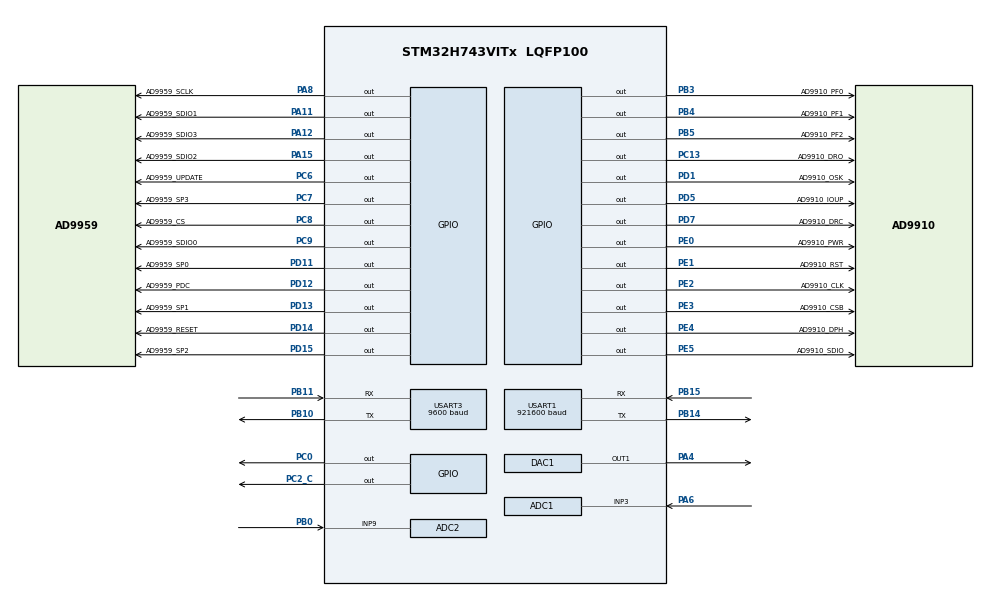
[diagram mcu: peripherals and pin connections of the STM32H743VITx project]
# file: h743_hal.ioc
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ADC1.Channel-0\#ChannelRegularConversion=ADC_CHANNEL_3
ADC1.ConversionDataManagement=ADC_CONVERSIONDATA_DMA_CIRCULAR
ADC1.ExternalTrigConv=ADC_EXTERNALTRIG_T6_TRGO
ADC1.NbrOfConversionFlag=1
ADC1.OffsetNumber-0\#ChannelRegularConversion=ADC_OFFSET_NONE
ADC1.OffsetSignedSaturation-0\#ChannelRegularConversion=DISABLE
ADC1.Rank-0\#ChannelRegularConversion=1
ADC1.Resolution=ADC_RESOLUTION_12B
ADC1.SamplingTime-0\#ChannelRegularConversion=ADC_SAMPLETIME_1CYCLE_5
ADC1.master=1
ADC2.Channel-7\#ChannelRegularConversion=ADC_CHANNEL_9
ADC2.ConversionDataManagement=ADC_CONVERSIONDATA_DMA_CIRCULAR
ADC2.ExternalTrigConv=ADC_EXTERNALTRIG_T6_TRGO
ADC2.NbrOfConversionFlag=1
ADC2.OffsetNumber-7\#ChannelRegularConversion=ADC_OFFSET_NONE
ADC2.OffsetSignedSaturation-7\#ChannelRegularConversion=DISABLE
ADC2.Rank-7\#ChannelRegularConversion=1
ADC2.Resolution=ADC_RESOLUTION_12B
ADC2.SamplingTime-7\#ChannelRegularConversion=ADC_SAMPLETIME_16CYCLES_5
CORTEX_M7.AccessPermission_Spec=MPU_REGION_FULL_ACCESS
CORTEX_M7.BaseAddress_Spec=0x24000000
CORTEX_M7.CPU_DCache=Enabled
CORTEX_M7.CPU_ICache=Enabled
CORTEX_M7.DisableExec_Spec=MPU_INSTRUCTION_ACCESS_ENABLE
CORTEX_M7.IsShareable_Spec=MPU_ACCESS_NOT_SHAREABLE
CORTEX_M7.Size_Spec=MPU_REGION_SIZE_128KB
CORTEX_M7.SubRegionDisable_Spec=0x00
CORTEX_M7.TypeExtField_Spec=MPU_TEX_LEVEL1
CORTEX_M7.default_mode_Activation=1
DAC1.DAC1_OutputBuffer-DAC_OUT1=DAC_OUTPUTBUFFER_ENABLE
DAC1.DAC_Channel-DAC_OUT1=DAC_CHANNEL_1
DAC1.DAC_Trigger-DAC_OUT1=DAC_TRIGGER_T6_TRGO
Dma.ADC1.0.Direction=DMA_PERIPH_TO_MEMORY
Dma.ADC1.0.EventEnable=DISABLE
Dma.ADC1.0.FIFOMode=DMA_FIFOMODE_DISABLE
Dma.ADC1.0.Instance=DMA1_Stream0
Dma.ADC1.0.MemDataAlignment=DMA_MDATAALIGN_HALFWORD
Dma.ADC1.0.MemInc=DMA_MINC_ENABLE
Dma.ADC1.0.Mode=DMA_CIRCULAR
Dma.ADC1.0.PeriphDataAlignment=DMA_PDATAALIGN_HALFWORD
Dma.ADC1.0.PeriphInc=DMA_PINC_DISABLE
Dma.ADC1.0.Polarity=HAL_DMAMUX_REQ_GEN_RISING
Dma.ADC1.0.Priority=DMA_PRIORITY_LOW
Dma.ADC1.0.RequestNumber=1
Dma.ADC1.0.SignalID=NONE
Dma.ADC1.0.SyncEnable=DISABLE
Dma.ADC1.0.SyncPolarity=HAL_DMAMUX_SYNC_NO_EVENT
Dma.ADC1.0.SyncRequestNumber=1
Dma.ADC1.0.SyncSignalID=NONE
Dma.ADC2.4.Direction=DMA_PERIPH_TO_MEMORY
Dma.ADC2.4.EventEnable=DISABLE
Dma.ADC2.4.FIFOMode=DMA_FIFOMODE_DISABLE
Dma.ADC2.4.Instance=DMA1_Stream4
Dma.ADC2.4.MemDataAlignment=DMA_MDATAALIGN_HALFWORD
Dma.ADC2.4.MemInc=DMA_MINC_ENABLE
Dma.ADC2.4.Mode=DMA_CIRCULAR
Dma.ADC2.4.PeriphDataAlignment=DMA_PDATAALIGN_HALFWORD
Dma.ADC2.4.PeriphInc=DMA_PINC_DISABLE
Dma.ADC2.4.Polarity=HAL_DMAMUX_REQ_GEN_RISING
Dma.ADC2.4.Priority=DMA_PRIORITY_VERY_HIGH
Dma.ADC2.4.RequestNumber=1
Dma.ADC2.4.SignalID=NONE
Dma.ADC2.4.SyncEnable=DISABLE
Dma.ADC2.4.SyncPolarity=HAL_DMAMUX_SYNC_NO_EVENT
Dma.ADC2.4.SyncRequestNumber=1
Dma.ADC2.4.SyncSignalID=NONE
Dma.DAC1_CH1.3.Direction=DMA_MEMORY_TO_PERIPH
Dma.DAC1_CH1.3.EventEnable=DISABLE
Dma.DAC1_CH1.3.FIFOMode=DMA_FIFOMODE_DISABLE
Dma.DAC1_CH1.3.Instance=DMA1_Stream3
Dma.DAC1_CH1.3.MemDataAlignment=DMA_MDATAALIGN_HALFWORD
Dma.DAC1_CH1.3.MemInc=DMA_MINC_ENABLE
Dma.DAC1_CH1.3.Mode=DMA_CIRCULAR
Dma.DAC1_CH1.3.PeriphDataAlignment=DMA_PDATAALIGN_HALFWORD
Dma.DAC1_CH1.3.PeriphInc=DMA_PINC_DISABLE
Dma.DAC1_CH1.3.Polarity=HAL_DMAMUX_REQ_GEN_RISING
Dma.DAC1_CH1.3.Priority=DMA_PRIORITY_VERY_HIGH
Dma.DAC1_CH1.3.RequestNumber=1
Dma.DAC1_CH1.3.SignalID=NONE
Dma.DAC1_CH1.3.SyncEnable=DISABLE
Dma.DAC1_CH1.3.SyncPolarity=HAL_DMAMUX_SYNC_NO_EVENT
Dma.DAC1_CH1.3.SyncRequestNumber=1
Dma.DAC1_CH1.3.SyncSignalID=NONE
Dma.Request0=ADC1
Dma.Request1=USART1_RX
Dma.Request2=USART3_RX
Dma.Request3=DAC1_CH1
Dma.Request4=ADC2
Dma.USART1_RX.1.Direction=DMA_PERIPH_TO_MEMORY
Dma.USART1_RX.1.EventEnable=DISABLE
Dma.USART1_RX.1.FIFOMode=DMA_FIFOMODE_DISABLE
Dma.USART1_RX.1.Instance=DMA1_Stream1
Dma.USART1_RX.1.MemDataAlignment=DMA_MDATAALIGN_BYTE
Dma.USART1_RX.1.MemInc=DMA_MINC_ENABLE
Dma.USART1_RX.1.Mode=DMA_NORMAL
Dma.USART1_RX.1.PeriphDataAlignment=DMA_PDATAALIGN_BYTE
Dma.USART1_RX.1.PeriphInc=DMA_PINC_DISABLE
Dma.USART1_RX.1.Polarity=HAL_DMAMUX_REQ_GEN_RISING
Dma.USART1_RX.1.Priority=DMA_PRIORITY_LOW
Dma.USART1_RX.1.RequestNumber=1
Dma.USART1_RX.1.SignalID=NONE
Dma.USART1_RX.1.SyncEnable=DISABLE
Dma.USART1_RX.1.SyncPolarity=HAL_DMAMUX_SYNC_NO_EVENT
Dma.USART1_RX.1.SyncRequestNumber=1
Dma.USART1_RX.1.SyncSignalID=NONE
Dma.USART3_RX.2.Direction=DMA_PERIPH_TO_MEMORY
Dma.USART3_RX.2.EventEnable=DISABLE
Dma.USART3_RX.2.FIFOMode=DMA_FIFOMODE_DISABLE
Dma.USART3_RX.2.Instance=DMA1_Stream2
Dma.USART3_RX.2.MemDataAlignment=DMA_MDATAALIGN_BYTE
Dma.USART3_RX.2.MemInc=DMA_MINC_ENABLE
Dma.USART3_RX.2.Mode=DMA_NORMAL
Dma.USART3_RX.2.PeriphDataAlignment=DMA_PDATAALIGN_BYTE
Dma.USART3_RX.2.PeriphInc=DMA_PINC_DISABLE
Dma.USART3_RX.2.Polarity=HAL_DMAMUX_REQ_GEN_RISING
Dma.USART3_RX.2.Priority=DMA_PRIORITY_LOW
Dma.USART3_RX.2.RequestNumber=1
Dma.USART3_RX.2.SignalID=NONE
Dma.USART3_RX.2.SyncEnable=DISABLE
Dma.USART3_RX.2.SyncPolarity=HAL_DMAMUX_SYNC_NO_EVENT
Dma.USART3_RX.2.SyncRequestNumber=1
Dma.USART3_RX.2.SyncSignalID=NONE
Mcu.Family=STM32H7
Mcu.Name=STM32H743VITx
Mcu.Package=LQFP100
NVIC.DMA1_Stream0_IRQn=true\:0\:0\:false\:false\:true\:false\:true\:true
NVIC.DMA1_Stream1_IRQn=true\:0\:0\:false\:false\:true\:false\:true\:true
NVIC.DMA1_Stream2_IRQn=true\:0\:0\:false\:false\:true\:false\:true\:true
NVIC.DMA1_Stream3_IRQn=true\:0\:0\:false\:false\:true\:false\:true\:true
NVIC.DMA1_Stream4_IRQn=true\:0\:0\:false\:false\:true\:false\:true\:true
NVIC.PriorityGroup=NVIC_PRIORITYGROUP_4
NVIC.USART3_IRQn=true\:0\:0\:false\:false\:true\:true\:true\:true
PA11.GPIO_Label=AD9959_SDIO1
PA11.Signal=GPIO_Output
PA12.GPIO_Label=AD9959_SDIO3
PA12.Signal=GPIO_Output
PA13\ (JTMS/SWDIO).Mode=Serial_Wire
PA13\ (JTMS/SWDIO).Signal=DEBUG_JTMS-SWDIO
PA14\ (JTCK/SWCLK).Mode=Serial_Wire
PA14\ (JTCK/SWCLK).Signal=DEBUG_JTCK-SWCLK
PA15\ (JTDI).GPIO_Label=AD9959_SDIO2
PA15\ (JTDI).Signal=GPIO_Output
PA4.Signal=COMP_DAC11_group
PA6.Signal=ADCx_INP3
PA8.GPIO_Label=AD9959_SCLK
PA8.Signal=GPIO_Output
PB0.Signal=ADCx_INP9
PB10.Mode=Asynchronous
PB10.Signal=USART3_TX
PB11.Mode=Asynchronous
PB11.Signal=USART3_RX
PB14.Mode=Asynchronous
PB14.Signal=USART1_TX
PB15.Mode=Asynchronous
PB15.Signal=USART1_RX
PB3\ (JTDO/TRACESWO).GPIO_Label=AD9910_PF0
PB3\ (JTDO/TRACESWO).Signal=GPIO_Output
PB4\ (NJTRST).GPIO_Label=AD9910_PF1
PB4\ (NJTRST).Signal=GPIO_Output
PB5.GPIO_Label=AD9910_PF2
PB5.Signal=GPIO_Output
PC0.Signal=GPIO_Output
PC13.GPIO_Label=AD9910_DRO
PC13.Signal=GPIO_Output
PC14-OSC32_IN\ (OSC32_IN).Mode=LSE-External-Oscillator
PC14-OSC32_IN\ (OSC32_IN).Signal=RCC_OSC32_IN
PC15-OSC32_OUT\ (OSC32_OUT).Mode=LSE-External-Oscillator
PC15-OSC32_OUT\ (OSC32_OUT).Signal=RCC_OSC32_OUT
PC2_C.Signal=GPIO_Output
PC6.GPIO_Label=AD9959_UPDATE
PC6.Signal=GPIO_Output
PC7.GPIO_Label=AD9959_SP3
PC7.Signal=GPIO_Output
PC8.GPIO_Label=AD9959_CS
PC8.Signal=GPIO_Output
PC9.GPIO_Label=AD9959_SDIO0
PC9.Signal=GPIO_Output
PD1.GPIO_Label=AD9910_OSK
PD1.Signal=GPIO_Output
PD11.GPIO_Label=AD9959_SP0
PD11.Signal=GPIO_Output
PD12.GPIO_Label=AD9959_PDC
PD12.Signal=GPIO_Output
PD13.GPIO_Label=AD9959_SP1
PD13.Signal=GPIO_Output
PD14.GPIO_Label=AD9959_RESET
PD14.Signal=GPIO_Output
PD15.GPIO_Label=AD9959_SP2
PD15.Signal=GPIO_Output
PD5.GPIO_Label=AD9910_IOUP
PD5.Signal=GPIO_Output
PD7.GPIO_Label=AD9910_DRC
PD7.Signal=GPIO_Output
PE0.GPIO_Label=AD9910_PWR
PE0.Signal=GPIO_Output
PE1.GPIO_Label=AD9910_RST
PE1.Signal=GPIO_Output
PE2.GPIO_Label=AD9910_CLK
PE2.GPIO_Speed=GPIO_SPEED_FREQ_VERY_HIGH
PE2.Signal=GPIO_Output
PE3.GPIO_Label=AD9910_CSB
PE3.Signal=GPIO_Output
PE4.GPIO_Label=AD9910_DPH
PE4.Signal=GPIO_Output
PE5.GPIO_Label=AD9910_SDIO
PE5.Signal=GPIO_Output
PH0-OSC_IN\ (PH0).Mode=HSE-External-Oscillator
PH0-OSC_IN\ (PH0).Signal=RCC_OSC_IN
PH1-OSC_OUT\ (PH1).Mode=HSE-External-Oscillator
PH1-OSC_OUT\ (PH1).Signal=RCC_OSC_OUT
ProjectManager.HeapSize=0x200
ProjectManager.StackSize=0x400
ProjectManager.TargetToolchain=MDK-ARM V5.32
RCC.ADCFreq_Value=75000000
RCC.APB1Freq_Value=120000000
RCC.APB2Freq_Value=120000000
RCC.APB3Freq_Value=120000000
RCC.APB4Freq_Value=120000000
RCC.CortexFreq_Value=480000000
RCC.D1PPRE=RCC_APB3_DIV2
RCC.D2PPRE1=RCC_APB1_DIV2
RCC.D2PPRE2=RCC_APB2_DIV2
RCC.D3PPRE=RCC_APB4_DIV2
RCC.DIVM1=5
RCC.DIVM2=2
RCC.DIVN1=192
RCC.DIVN2=12
RCC.HCLKFreq_Value=240000000
RCC.HPRE=RCC_HCLK_DIV2
RCC.PLL2FRACN=0
RCC.PLL3FRACN=0
RCC.PLLFRACN=0
RCC.PLLSourceVirtual=RCC_PLLSOURCE_HSE
RCC.SYSCLKFreq_VALUE=480000000
RCC.SYSCLKSource=RCC_SYSCLKSOURCE_PLLCLK
RCC.USBFreq_Value=480000000
SH.ADCx_INP3.0=ADC2_INP3
SH.ADCx_INP3.1=ADC1_INP3,IN3-Single-Ended
SH.ADCx_INP9.0=ADC2_INP9,IN9-Single-Ended
SH.COMP_DAC11_group.0=DAC1_OUT1,DAC_OUT1
TIM6.AutoReloadPreload=TIM_AUTORELOAD_PRELOAD_ENABLE
TIM6.Period=40-1
TIM6.Prescaler=4-1
TIM6.TIM_MasterOutputTrigger=TIM_TRGO_UPDATE
USART1.BaudRate=921600
USART1.VirtualMode-Asynchronous=VM_ASYNC
USART3.BaudRate=9600
USART3.VirtualMode-Asynchronous=VM_ASYNC
VP_MEMORYMAP_VS_MEMORYMAP.Mode=CurAppReg
VP_TIM6_VS_ClockSourceINT.Mode=Enable_Timer
board=custom

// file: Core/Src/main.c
/* USER CODE BEGIN Header */
/**
  ******************************************************************************
  * @file           : main.c
  * @brief          : Main program body
  ******************************************************************************
  * @attention
  *
  * Copyright (c) 2026 STMicroelectronics.
  * All rights reserved.
  *
  * This software is licensed under terms that can be found in the LICENSE file
  * in the root directory of this software component.
  * If no LICENSE file comes with this software, it is provided AS-IS.
  *
  ******************************************************************************
  */
/* USER CODE END Header */
#include "main.h"
#include "adc.h"
#include "dac.h"
#include "dma.h"
#include "tim.h"
#include "usart.h"
#include "gpio.h"

/* USER CODE BEGIN Includes */
#include "rlc_app.h"

/* USER CODE END Includes */

void SystemClock_Config(void);
void PeriphCommonClock_Config(void);
static void MPU_Config(void);

int main(void)
{

  /* MPU Configuration--------------------------------------------------------*/
  MPU_Config();

  /* Enable the CPU Cache */

  /* Enable I-Cache---------------------------------------------------------*/
  SCB_EnableICache();

  /* Enable D-Cache---------------------------------------------------------*/
  SCB_EnableDCache();

  /* MCU Configuration--------------------------------------------------------*/

  /* Reset of all peripherals, Initializes the Flash interface and the Systick. */
  HAL_Init();

  /* Configure the system clock */
  SystemClock_Config();

  /* Configure the peripherals common clocks */
  PeriphCommonClock_Config();

  /* Initialize all configured peripherals */
  MX_GPIO_Init();
  MX_DMA_Init();
  MX_ADC1_Init();
  MX_USART3_UART_Init();
  MX_USART1_UART_Init();
  MX_DAC1_Init();
  MX_TIM6_Init();
  MX_ADC2_Init();
  /* USER CODE BEGIN 2 */
  rlc_app_init();
  /* USER CODE END 2 */

  /* Infinite loop */
  while (1)
  {

    /* USER CODE BEGIN 3 */
    rlc_app_task();
  }
  /* USER CODE END 3 */
}

void SystemClock_Config(void)
{
  RCC_OscInitTypeDef RCC_OscInitStruct = {0};
  RCC_ClkInitTypeDef RCC_ClkInitStruct = {0};

  /** Supply configuration update enable
  */
  HAL_PWREx_ConfigSupply(PWR_LDO_SUPPLY);

  /** Configure the main internal regulator output voltage
  */
  __HAL_PWR_VOLTAGESCALING_CONFIG(PWR_REGULATOR_VOLTAGE_SCALE0);

  while(!__HAL_PWR_GET_FLAG(PWR_FLAG_VOSRDY)) {}

  /** Initializes the RCC Oscillators according to the specified parameters
  * in the RCC_OscInitTypeDef structure.
  */
  RCC_OscInitStruct.OscillatorType = RCC_OSCILLATORTYPE_HSE;
  RCC_OscInitStruct.HSEState = RCC_HSE_ON;
  RCC_OscInitStruct.PLL.PLLState = RCC_PLL_ON;
  RCC_OscInitStruct.PLL.PLLSource = RCC_PLLSOURCE_HSE;
  RCC_OscInitStruct.PLL.PLLM = 5;
  RCC_OscInitStruct.PLL.PLLN = 192;
  RCC_OscInitStruct.PLL.PLLP = 2;
  RCC_OscInitStruct.PLL.PLLQ = 2;
  RCC_OscInitStruct.PLL.PLLR = 2;
  RCC_OscInitStruct.PLL.PLLRGE = RCC_PLL1VCIRANGE_2;
  RCC_OscInitStruct.PLL.PLLVCOSEL = RCC_PLL1VCOWIDE;
  RCC_OscInitStruct.PLL.PLLFRACN = 0;
  if (HAL_RCC_OscConfig(&RCC_OscInitStruct) != HAL_OK)
  {
    Error_Handler();
  }

  /** Initializes the CPU, AHB and APB buses clocks
  */
  RCC_ClkInitStruct.ClockType = RCC_CLOCKTYPE_HCLK|RCC_CLOCKTYPE_SYSCLK
                              |RCC_CLOCKTYPE_PCLK1|RCC_CLOCKTYPE_PCLK2
                              |RCC_CLOCKTYPE_D3PCLK1|RCC_CLOCKTYPE_D1PCLK1;
  RCC_ClkInitStruct.SYSCLKSource = RCC_SYSCLKSOURCE_PLLCLK;
  RCC_ClkInitStruct.SYSCLKDivider = RCC_SYSCLK_DIV1;
  RCC_ClkInitStruct.AHBCLKDivider = RCC_HCLK_DIV2;
  RCC_ClkInitStruct.APB3CLKDivider = RCC_APB3_DIV2;
  RCC_ClkInitStruct.APB1CLKDivider = RCC_APB1_DIV2;
  RCC_ClkInitStruct.APB2CLKDivider = RCC_APB2_DIV2;
  RCC_ClkInitStruct.APB4CLKDivider = RCC_APB4_DIV2;

  if (HAL_RCC_ClockConfig(&RCC_ClkInitStruct, FLASH_LATENCY_4) != HAL_OK)
  {
    Error_Handler();
  }
}

void PeriphCommonClock_Config(void)
{
  RCC_PeriphCLKInitTypeDef PeriphClkInitStruct = {0};

  /** Initializes the peripherals clock
  */
  PeriphClkInitStruct.PeriphClockSelection = RCC_PERIPHCLK_ADC;
  PeriphClkInitStruct.PLL2.PLL2M = 2;
  PeriphClkInitStruct.PLL2.PLL2N = 12;
  PeriphClkInitStruct.PLL2.PLL2P = 2;
  PeriphClkInitStruct.PLL2.PLL2Q = 2;
  PeriphClkInitStruct.PLL2.PLL2R = 2;
  PeriphClkInitStruct.PLL2.PLL2RGE = RCC_PLL2VCIRANGE_3;
  PeriphClkInitStruct.PLL2.PLL2VCOSEL = RCC_PLL2VCOMEDIUM;
  PeriphClkInitStruct.PLL2.PLL2FRACN = 0;
  PeriphClkInitStruct.AdcClockSelection = RCC_ADCCLKSOURCE_PLL2;
  if (HAL_RCCEx_PeriphCLKConfig(&PeriphClkInitStruct) != HAL_OK)
  {
    Error_Handler();
  }
}

 /* MPU Configuration */

void MPU_Config(void)
{
  MPU_Region_InitTypeDef MPU_InitStruct = {0};

  /* Disables the MPU */
  HAL_MPU_Disable();

  /** Initializes and configures the Region and the memory to be protected
  */
  MPU_InitStruct.Enable = MPU_REGION_ENABLE;
  MPU_InitStruct.Number = MPU_REGION_NUMBER0;
  MPU_InitStruct.BaseAddress = 0x24000000;
  MPU_InitStruct.Size = MPU_REGION_SIZE_128KB;
  MPU_InitStruct.SubRegionDisable = 0x00;
  MPU_InitStruct.TypeExtField = MPU_TEX_LEVEL1;
  MPU_InitStruct.AccessPermission = MPU_REGION_FULL_ACCESS;
  MPU_InitStruct.DisableExec = MPU_INSTRUCTION_ACCESS_ENABLE;
  MPU_InitStruct.IsShareable = MPU_ACCESS_NOT_SHAREABLE;
  MPU_InitStruct.IsCacheable = MPU_ACCESS_NOT_CACHEABLE;
  MPU_InitStruct.IsBufferable = MPU_ACCESS_NOT_BUFFERABLE;

  HAL_MPU_ConfigRegion(&MPU_InitStruct);
  /* Enables the MPU */
  HAL_MPU_Enable(MPU_PRIVILEGED_DEFAULT);

}

void Error_Handler(void)
{
  __disable_irq();
  while (1)
  {
  }
}
